# STM32WB55_CM0P register map
File version: 1.7
CPU: CM0 r0p1, little endian, MPU, no FPU, 4 interrupt priority bits
Registers are 32-bit, read-write, reset 0x0 unless marked. A register's access mark holds for its fields unless they carry their own. Offsets are from the block's base; [hi:lo] are bit positions.

## RCC — Reset and clock control
Base 0x58000000
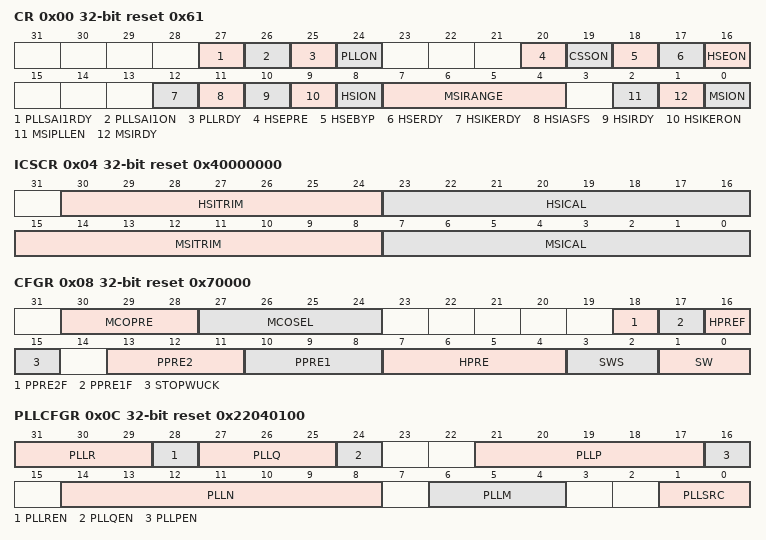
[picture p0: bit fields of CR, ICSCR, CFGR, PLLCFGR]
0x00 CR access per field reset 0x61 — Clock control register
  [27] PLLSAI1RDY ro — SAI1 PLL clock ready flag
  [26] PLLSAI1ON rw — SAI1 PLL enable
  [25] PLLRDY ro — Main PLL clock ready flag
  [24] PLLON rw — Main PLL enable
  [20] HSEPRE rw — HSE sysclk and PLL M divider prescaler
  [19] CSSON wo — HSE Clock security system enable
  [18] HSEBYP rw — HSE crystal oscillator bypass
  [17] HSERDY ro — HSE clock ready flag
  [16] HSEON rw — HSE clock enabled
  [12] HSIKERDY ro — HSI kernel clock ready flag for peripherals requests
  [11] HSIASFS rw — HSI automatic start from Stop
  [10] HSIRDY ro — HSI clock ready flag
  [9] HSIKERON rw — HSI always enable for peripheral kernels
  [8] HSION rw — HSI clock enabled
  [7:4] MSIRANGE rw — MSI clock ranges
  [2] MSIPLLEN rw — MSI clock PLL enable
  [1] MSIRDY ro — MSI clock ready flag
  [0] MSION rw — MSI clock enable
0x04 ICSCR access per field reset 0x40000000 — Internal clock sources calibration register
  [30:24] HSITRIM rw — HSI clock trimming
  [23:16] HSICAL ro — HSI clock calibration
  [15:8] MSITRIM rw — MSI clock trimming
  [7:0] MSICAL ro — MSI clock calibration
0x08 CFGR access per field reset 0x70000 — Clock configuration register
  [30:28] MCOPRE rw — Microcontroller clock output prescaler
  [27:24] MCOSEL rw — Microcontroller clock output
  [18] PPRE2F ro — APB2 prescaler flag
  [17] PPRE1F ro — APB1 prescaler flag
  [16] HPREF ro — AHB prescaler flag
  [15] STOPWUCK rw — Wakeup from Stop and CSS backup clock selection
  [13:11] PPRE2 rw — APB high-speed prescaler (APB2)
  [10:8] PPRE1 rw — PB low-speed prescaler (APB1)
  [7:4] HPRE rw — AHB prescaler
  [3:2] SWS ro — System clock switch status
  [1:0] SW rw — System clock switch
0x0C PLLCFGR reset 0x22040100 — PLLSYS configuration register
  [31:29] PLLR — Main PLLSYS division factor R for SYSCLK (system clock)
  [28] PLLREN — Main PLLSYSR PLLCLK output enable
  [27:25] PLLQ — Main PLLSYS division factor Q for PLLSYSUSBCLK
  [24] PLLQEN — Main PLLSYSQ output enable
  [21:17] PLLP — Main PLL division factor P for PPLSYSSAICLK
  [16] PLLPEN — Main PLLSYSP output enable
  [14:8] PLLN — Main PLLSYS multiplication factor N
  [6:4] PLLM — Division factor M for the main PLL and audio PLL (PLLSAI1 and PLLSAI2) input clock
  [1:0] PLLSRC — Main PLL, PLLSAI1 and PLLSAI2 entry clock source
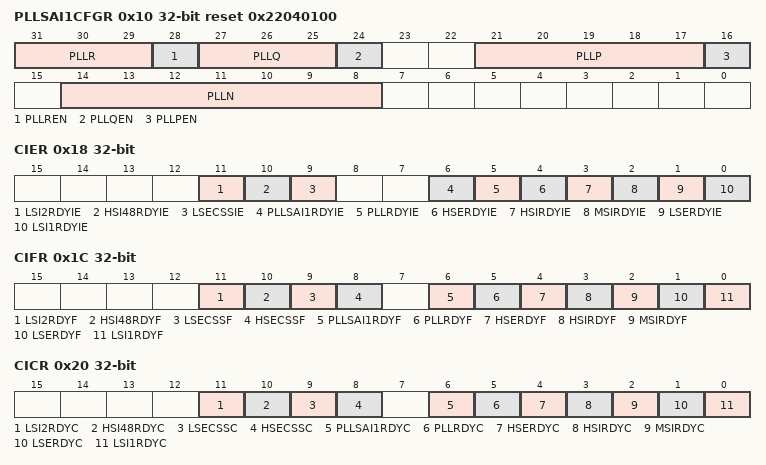
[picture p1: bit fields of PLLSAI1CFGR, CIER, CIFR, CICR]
0x10 PLLSAI1CFGR reset 0x22040100 — PLLSAI1 configuration register
  [31:29] PLLR — PLLSAI division factor R for PLLADC1CLK (ADC clock)
  [28] PLLREN — PLLSAI PLLADC1CLK output enable
  [27:25] PLLQ — SAIPLL division factor Q for PLLSAIUSBCLK (48 MHz clock)
  [24] PLLQEN — SAIPLL PLLSAIUSBCLK output enable
  [21:17] PLLP — SAI1PLL division factor P for PLLSAICLK (SAI1clock)
  [16] PLLPEN — SAIPLL PLLSAI1CLK output enable
  [14:8] PLLN — SAIPLL multiplication factor for VCO
0x18 CIER — Clock interrupt enable register
  [11] LSI2RDYIE — LSI2 ready interrupt enable
  [10] HSI48RDYIE — HSI48 ready interrupt enable
  [9] LSECSSIE — LSE clock security system interrupt enable
  [6] PLLSAI1RDYIE — PLLSAI1 ready interrupt enable
  [5] PLLRDYIE — PLLSYS ready interrupt enable
  [4] HSERDYIE — HSE ready interrupt enable
  [3] HSIRDYIE — HSI ready interrupt enable
  [2] MSIRDYIE — MSI ready interrupt enable
  [1] LSERDYIE — LSE ready interrupt enable
  [0] LSI1RDYIE — LSI1 ready interrupt enable
0x1C CIFR ro — Clock interrupt flag register
  [11] LSI2RDYF — LSI2 ready interrupt flag
  [10] HSI48RDYF — HSI48 ready interrupt flag
  [9] LSECSSF — LSE Clock security system interrupt flag
  [8] HSECSSF — HSE Clock security system interrupt flag
  [6] PLLSAI1RDYF — PLLSAI1 ready interrupt flag
  [5] PLLRDYF — PLL ready interrupt flag
  [4] HSERDYF — HSE ready interrupt flag
  [3] HSIRDYF — HSI ready interrupt flag
  [2] MSIRDYF — MSI ready interrupt flag
  [1] LSERDYF — LSE ready interrupt flag
  [0] LSI1RDYF — LSI1 ready interrupt flag
0x20 CICR wo — Clock interrupt clear register
  [11] LSI2RDYC — LSI2 ready interrupt clear
  [10] HSI48RDYC — HSI48 ready interrupt clear
  [9] LSECSSC — LSE Clock security system interrupt clear
  [8] HSECSSC — HSE Clock security system interrupt clear
  [6] PLLSAI1RDYC — PLLSAI1 ready interrupt clear
  [5] PLLRDYC — PLL ready interrupt clear
  [4] HSERDYC — HSE ready interrupt clear
  [3] HSIRDYC — HSI ready interrupt clear
  [2] MSIRDYC — MSI ready interrupt clear
  [1] LSERDYC — LSE ready interrupt clear
  [0] LSI1RDYC — LSI1 ready interrupt clear
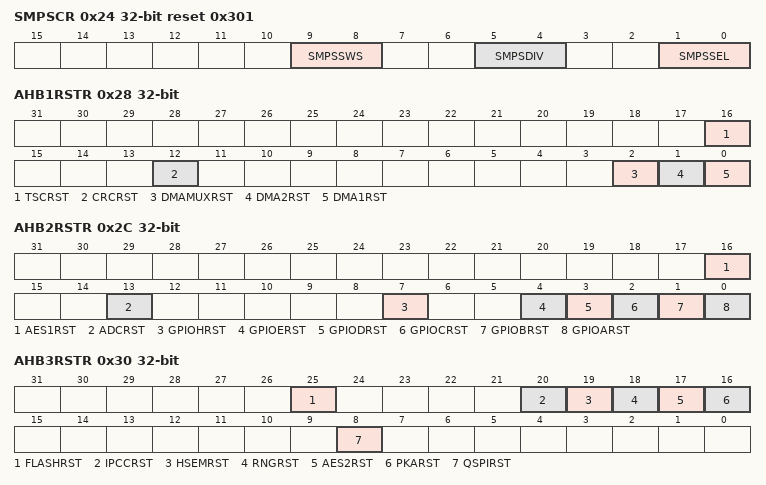
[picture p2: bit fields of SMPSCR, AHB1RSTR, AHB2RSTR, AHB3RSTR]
0x24 SMPSCR access per field reset 0x301 — Step Down converter control register
  [9:8] SMPSSWS ro — Step Down converter clock switch status
  [5:4] SMPSDIV rw — Step Down converter clock prescaler
  [1:0] SMPSSEL rw — Step Down converter clock selection
0x28 AHB1RSTR — AHB1 peripheral reset register
  [16] TSCRST — Touch Sensing Controller reset
  [12] CRCRST — CRC reset
  [2] DMAMUXRST — DMAMUX reset
  [1] DMA2RST — DMA2 reset
  [0] DMA1RST — DMA1 reset
0x2C AHB2RSTR — AHB2 peripheral reset register
  [16] AES1RST — AES1 hardware accelerator reset
  [13] ADCRST — ADC reset
  [7] GPIOHRST — IO port H reset
  [4] GPIOERST — IO port E reset
  [3] GPIODRST — IO port D reset
  [2] GPIOCRST — IO port C reset
  [1] GPIOBRST — IO port B reset
  [0] GPIOARST — IO port A reset
0x30 AHB3RSTR — AHB3 peripheral reset register
  [25] FLASHRST — Flash interface reset
  [20] IPCCRST — IPCC interface reset
  [19] HSEMRST — HSEM interface reset
  [18] RNGRST — RNG interface reset
  [17] AES2RST — AES2 interface reset
  [16] PKARST — PKA interface reset
  [8] QSPIRST — Quad SPI memory interface reset
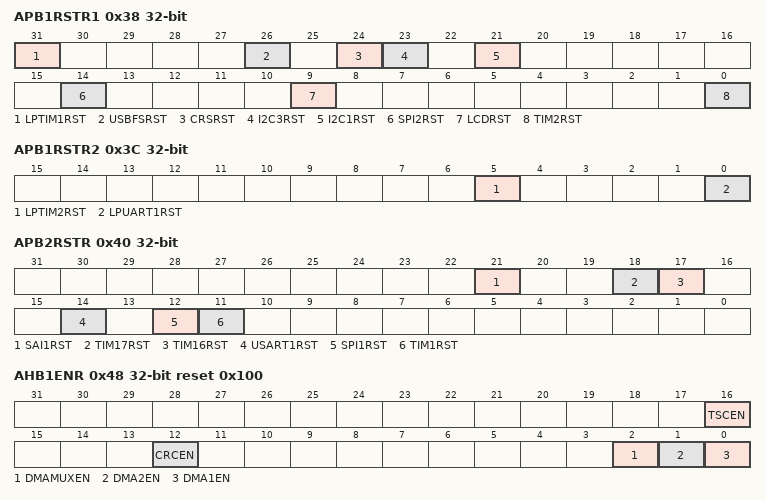
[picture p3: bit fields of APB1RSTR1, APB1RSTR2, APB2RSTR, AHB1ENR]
0x38 APB1RSTR1 — APB1 peripheral reset register 1
  [31] LPTIM1RST — Low Power Timer 1 reset
  [26] USBFSRST — USB FS reset
  [24] CRSRST — CRS reset
  [23] I2C3RST — I2C3 reset
  [21] I2C1RST — I2C1 reset
  [14] SPI2RST — SPI2 reset
  [9] LCDRST — LCD interface reset
  [0] TIM2RST — TIM2 timer reset
0x3C APB1RSTR2 — APB1 peripheral reset register 2
  [5] LPTIM2RST — Low-power timer 2 reset
  [0] LPUART1RST — Low-power UART 1 reset
0x40 APB2RSTR — APB2 peripheral reset register
  [21] SAI1RST — Serial audio interface 1 (SAI1) reset
  [18] TIM17RST — TIM17 timer reset
  [17] TIM16RST — TIM16 timer reset
  [14] USART1RST — USART1 reset
  [12] SPI1RST — SPI1 reset
  [11] TIM1RST — TIM1 timer reset
0x44 APB3RSTR — APB3 peripheral reset register
  [0] RFRST — Radio system BLE reset
0x48 AHB1ENR reset 0x100 — AHB1 peripheral clock enable register
  [16] TSCEN — Touch Sensing Controller clock enable
  [12] CRCEN — CPU1 CRC clock enable
  [2] DMAMUXEN — DMAMUX clock enable
  [1] DMA2EN — DMA2 clock enable
  [0] DMA1EN — DMA1 clock enable
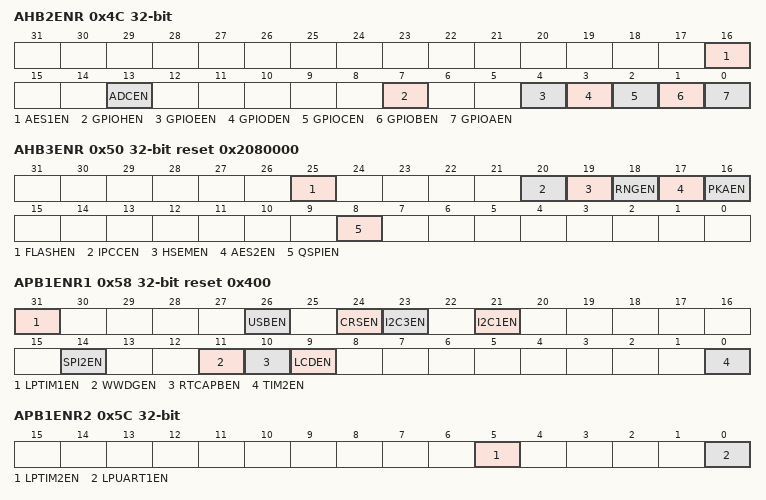
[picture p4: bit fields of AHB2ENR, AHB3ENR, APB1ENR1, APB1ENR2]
0x4C AHB2ENR — AHB2 peripheral clock enable register
  [16] AES1EN — AES1 accelerator clock enable
  [13] ADCEN — ADC clock enable
  [7] GPIOHEN — IO port H clock enable
  [4] GPIOEEN — IO port E clock enable
  [3] GPIODEN — IO port D clock enable
  [2] GPIOCEN — IO port C clock enable
  [1] GPIOBEN — IO port B clock enable
  [0] GPIOAEN — IO port A clock enable
0x50 AHB3ENR reset 0x2080000 — AHB3 peripheral clock enable register
  [25] FLASHEN, [20] IPCCEN, [19] HSEMEN, [18] RNGEN, [17] AES2EN, [16] PKAEN, [8] QSPIEN
0x58 APB1ENR1 reset 0x400
  [31] LPTIM1EN — CPU1 Low power timer 1 clock enable
  [26] USBEN — CPU1 USB clock enable
  [24] CRSEN — CPU1 CRS clock enable
  [23] I2C3EN — CPU1 I2C3 clock enable
  [21] I2C1EN — CPU1 I2C1 clock enable
  [14] SPI2EN — CPU1 SPI2 clock enable
  [11] WWDGEN — CPU1 Window watchdog clock enable
  [10] RTCAPBEN — CPU1 RTC APB clock enable
  [9] LCDEN — CPU1 LCD clock enable
  [0] TIM2EN — CPU1 TIM2 timer clock enable
0x5C APB1ENR2 — APB1 peripheral clock enable register 2
  [5] LPTIM2EN — CPU1 LPTIM2EN
  [0] LPUART1EN — CPU1 Low power UART 1 clock enable
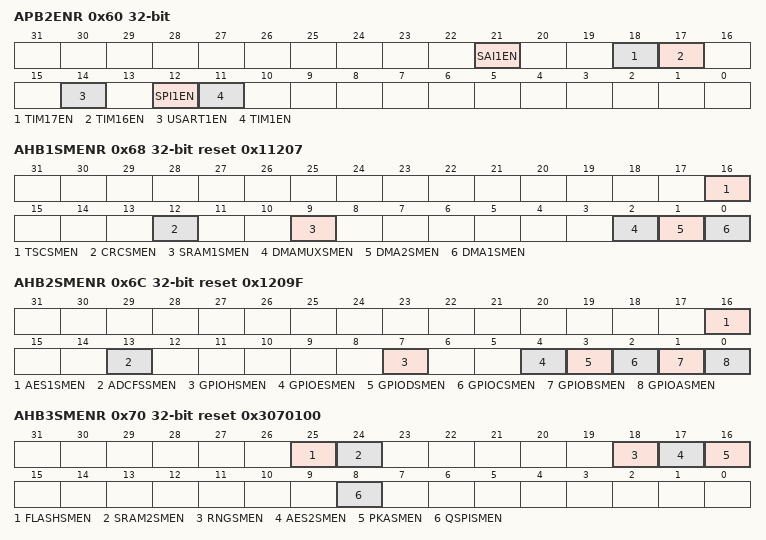
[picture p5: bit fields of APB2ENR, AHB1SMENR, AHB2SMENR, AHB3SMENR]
0x60 APB2ENR
  [21] SAI1EN — CPU1 SAI1 clock enable
  [18] TIM17EN — CPU1 TIM17 timer clock enable
  [17] TIM16EN — CPU1 TIM16 timer clock enable
  [14] USART1EN — CPU1 USART1clock enable
  [12] SPI1EN — CPU1 SPI1 clock enable
  [11] TIM1EN — CPU1 TIM1 timer clock enable
0x68 AHB1SMENR reset 0x11207 — AHB1 peripheral clocks enable in Sleep and Stop modes register
  [16] TSCSMEN — CPU1 Touch Sensing Controller clocks enable during Sleep and Stop modes
  [12] CRCSMEN — CPU1 CRCSMEN
  [9] SRAM1SMEN — CPU1 SRAM1 interface clocks enable during Sleep and Stop modes
  [2] DMAMUXSMEN — CPU1 DMAMUX clocks enable during Sleep and Stop modes
  [1] DMA2SMEN — CPU1 DMA2 clocks enable during Sleep and Stop modes
  [0] DMA1SMEN — CPU1 DMA1 clocks enable during Sleep and Stop modes
0x6C AHB2SMENR reset 0x1209F — AHB2 peripheral clocks enable in Sleep and Stop modes register
  [16] AES1SMEN — CPU1 AES1 accelerator clocks enable during Sleep and Stop modes
  [13] ADCFSSMEN — CPU1 ADC clocks enable during Sleep and Stop modes
  [7] GPIOHSMEN — CPU1 IO port H clocks enable during Sleep and Stop modes
  [4] GPIOESMEN — CPU1 IO port E clocks enable during Sleep and Stop modes
  [3] GPIODSMEN — CPU1 IO port D clocks enable during Sleep and Stop modes
  [2] GPIOCSMEN — CPU1 IO port C clocks enable during Sleep and Stop modes
  [1] GPIOBSMEN — CPU1 IO port B clocks enable during Sleep and Stop modes
  [0] GPIOASMEN — CPU1 IO port A clocks enable during Sleep and Stop modes
0x70 AHB3SMENR reset 0x3070100 — AHB3 peripheral clocks enable in Sleep and Stop modes register
  [25] FLASHSMEN — Flash interface clocks enable during CPU1 sleep mode
  [24] SRAM2SMEN — SRAM2a and SRAM2b memory interface clocks enable during CPU1 sleep mode
  [18] RNGSMEN — True RNG clocks enable during CPU1 sleep mode
  [17] AES2SMEN — AES2 accelerator clocks enable during CPU1 sleep mode
  [16] PKASMEN — PKA accelerator clocks enable during CPU1 sleep mode
  [8] QSPISMEN
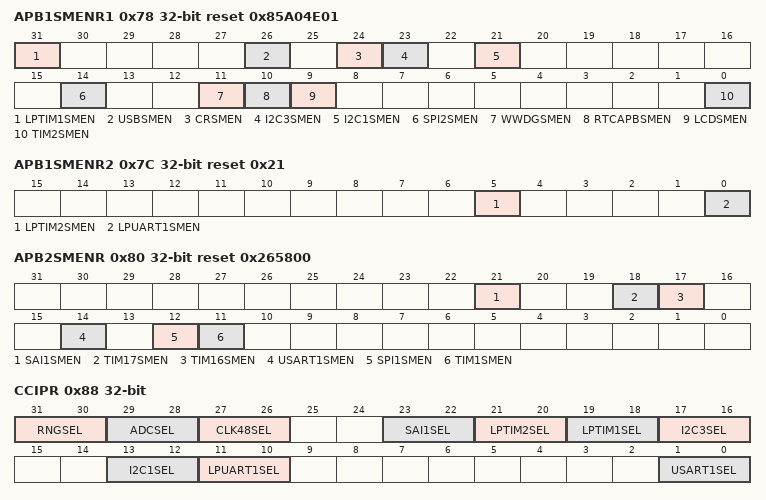
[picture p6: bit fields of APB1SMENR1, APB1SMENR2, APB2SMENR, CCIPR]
0x78 APB1SMENR1 reset 0x85A04E01
  [31] LPTIM1SMEN — Low power timer 1 clocks enable during CPU1 Sleep mode
  [26] USBSMEN — USB FS clocks enable during CPU1 Sleep mode
  [24] CRSMEN — CRS clocks enable during CPU1 Sleep mode
  [23] I2C3SMEN — I2C3 clocks enable during CPU1 Sleep mode
  [21] I2C1SMEN — I2C1 clocks enable during CPU1 Sleep mode
  [14] SPI2SMEN — SPI2 clocks enable during CPU1 Sleep mode
  [11] WWDGSMEN — Window watchdog clocks enable during CPU1 Sleep mode
  [10] RTCAPBSMEN — RTC APB clocks enable during CPU1 Sleep mode
  [9] LCDSMEN — LCD clocks enable during CPU1 Sleep mode
  [0] TIM2SMEN — TIM2 timer clocks enable during CPU1 Sleep mode
0x7C APB1SMENR2 reset 0x21 — APB1 peripheral clocks enable in Sleep and Stop modes register 2
  [5] LPTIM2SMEN — Low power timer 2 clocks enable during CPU1 Sleep mode
  [0] LPUART1SMEN — Low power UART 1 clocks enable during CPU1 Sleep mode
0x80 APB2SMENR reset 0x265800
  [21] SAI1SMEN — SAI1 clocks enable during CPU1 Sleep mode
  [18] TIM17SMEN — TIM17 timer clocks enable during CPU1 Sleep mode
  [17] TIM16SMEN — TIM16 timer clocks enable during CPU1 Sleep mode
  [14] USART1SMEN — USART1clocks enable during CPU1 Sleep mode
  [12] SPI1SMEN — SPI1 clocks enable during CPU1 Sleep mode
  [11] TIM1SMEN — TIM1 timer clocks enable during CPU1 Sleep mode
0x88 CCIPR
  [31:30] RNGSEL — RNG clock source selection
  [29:28] ADCSEL — ADCs clock source selection
  [27:26] CLK48SEL — 48 MHz clock source selection
  [23:22] SAI1SEL — SAI1 clock source selection
  [21:20] LPTIM2SEL — Low power timer 2 clock source selection
  [19:18] LPTIM1SEL — Low power timer 1 clock source selection
  [17:16] I2C3SEL — I2C3 clock source selection
  [13:12] I2C1SEL — I2C1 clock source selection
  [11:10] LPUART1SEL — LPUART1 clock source selection
  [1:0] USART1SEL — USART1 clock source selection
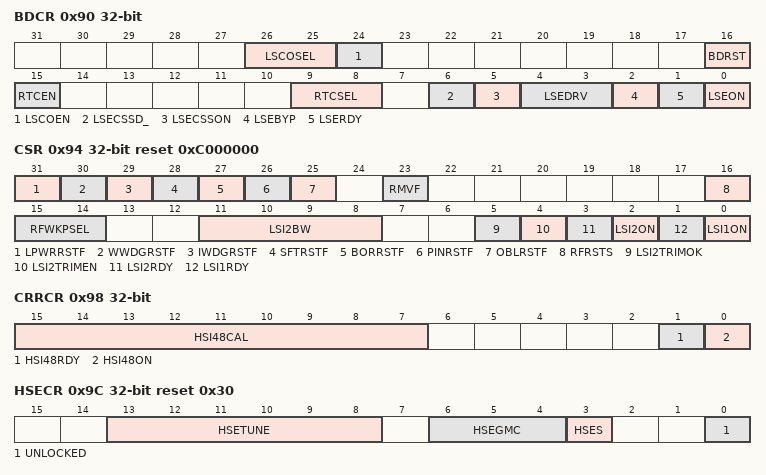
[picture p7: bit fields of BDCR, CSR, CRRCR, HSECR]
0x90 BDCR access per field
  [26:25] LSCOSEL rw — Low speed clock output selection
  [24] LSCOEN rw — Low speed clock output enable
  [16] BDRST rw — Backup domain software reset
  [15] RTCEN rw — RTC clock enable
  [9:8] RTCSEL rw — RTC clock source selection
  [6] LSECSSD_ ro — CSS on LSE failure detection
  [5] LSECSSON rw
  [4:3] LSEDRV rw — SE oscillator drive capability
  [2] LSEBYP rw — LSE oscillator bypass
  [1] LSERDY ro — LSE oscillator ready
  [0] LSEON rw — LSE oscillator enable
0x94 CSR access per field reset 0xC000000
  [31] LPWRRSTF ro — Low-power reset flag
  [30] WWDGRSTF ro — Window watchdog reset flag
  [29] IWDGRSTF ro — Independent window watchdog reset flag
  [28] SFTRSTF ro — Software reset flag
  [27] BORRSTF ro — BOR flag
  [26] PINRSTF ro — Pin reset flag
  [25] OBLRSTF ro — Option byte loader reset flag
  [23] RMVF rw — Remove reset flag
  [16] RFRSTS ro — Radio system BLE and 802.15.4 reset status
  [15:14] RFWKPSEL rw — RF system wakeup clock source selection
  [11:8] LSI2BW rw — LSI2 oscillator bias configuration
  [5] LSI2TRIMOK ro — LSI2 oscillator trim OK
  [4] LSI2TRIMEN rw — LSI2 oscillator trimming enable
  [3] LSI2RDY ro — LSI2 oscillator ready
  [2] LSI2ON rw — LSI2 oscillator enabled
  [1] LSI1RDY ro — LSI1 oscillator ready
  [0] LSI1ON rw — LSI1 oscillator enabled
0x98 CRRCR access per field — Clock recovery RC register
  [15:7] HSI48CAL ro — HSI48 clock calibration
  [1] HSI48RDY ro — HSI48 clock ready
  [0] HSI48ON rw — HSI48 oscillator enabled
0x9C HSECR access per field reset 0x30 — Clock HSE register
  [13:8] HSETUNE ro — HSE capacitor tuning
  [6:4] HSEGMC rw — HSE current control
  [3] HSES rw — HSE Sense amplifier threshold
  [0] UNLOCKED rw — Register lock system
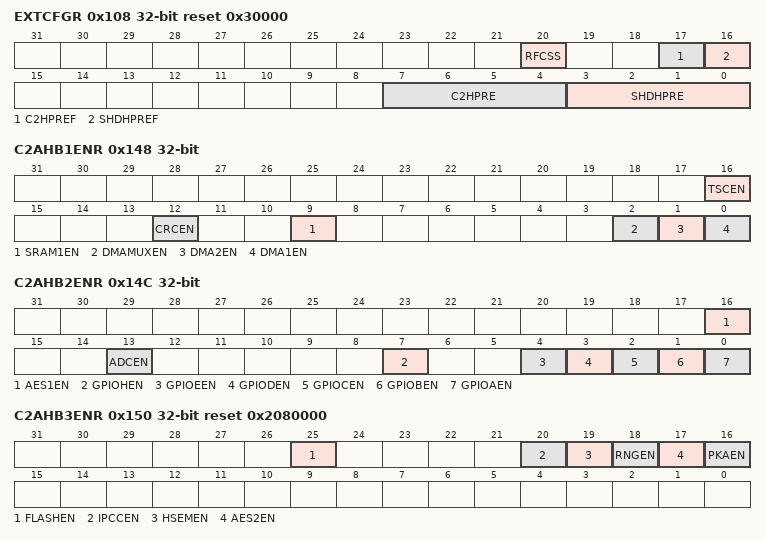
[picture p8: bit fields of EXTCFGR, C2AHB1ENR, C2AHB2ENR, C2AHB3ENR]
0x108 EXTCFGR access per field reset 0x30000 — Extended clock recovery register
  [20] RFCSS ro — RF clock source selected
  [17] C2HPREF ro — CPU2 AHB prescaler flag
  [16] SHDHPREF ro — Shared AHB prescaler flag
  [7:4] C2HPRE rw — CPU2 AHB prescaler
  [3:0] SHDHPRE rw — Shared AHB prescaler
0x148 C2AHB1ENR — CPU2 AHB1 peripheral clock enable register
  [16] TSCEN — CPU2 Touch Sensing Controller clock enable
  [12] CRCEN — CPU2 CRC clock enable
  [9] SRAM1EN — CPU2 SRAM1 clock enable
  [2] DMAMUXEN — CPU2 DMAMUX clock enable
  [1] DMA2EN — CPU2 DMA2 clock enable
  [0] DMA1EN — CPU2 DMA1 clock enable
0x14C C2AHB2ENR — CPU2 AHB2 peripheral clock enable register
  [16] AES1EN — CPU2 AES1 accelerator clock enable
  [13] ADCEN — CPU2 ADC clock enable
  [7] GPIOHEN — CPU2 IO port H clock enable
  [4] GPIOEEN — CPU2 IO port E clock enable
  [3] GPIODEN — CPU2 IO port D clock enable
  [2] GPIOCEN — CPU2 IO port C clock enable
  [1] GPIOBEN — CPU2 IO port B clock enable
  [0] GPIOAEN — CPU2 IO port A clock enable
0x150 C2AHB3ENR reset 0x2080000 — CPU2 AHB3 peripheral clock enable register
  [25] FLASHEN — CPU2 FLASHEN
  [20] IPCCEN — CPU2 IPCCEN
  [19] HSEMEN — CPU2 HSEMEN
  [18] RNGEN — CPU2 RNGEN
  [17] AES2EN — CPU2 AES2EN
  [16] PKAEN — CPU2 PKAEN
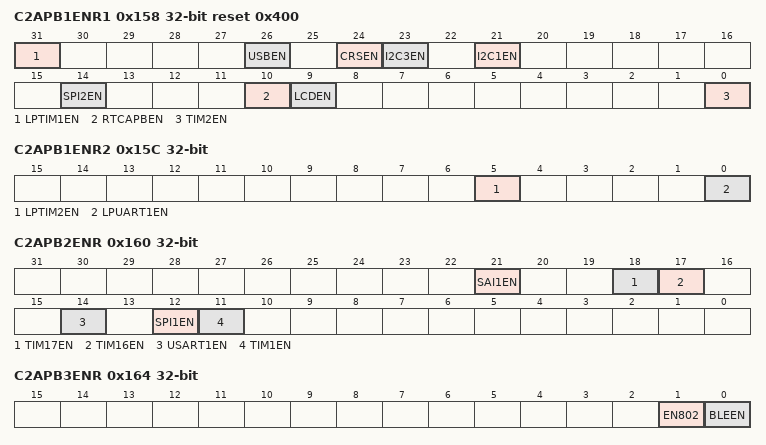
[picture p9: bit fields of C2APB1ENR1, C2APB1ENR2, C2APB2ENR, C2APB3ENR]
0x158 C2APB1ENR1 reset 0x400 — CPU2 APB1ENR1
  [31] LPTIM1EN — CPU2 Low power timer 1 clock enable
  [26] USBEN — CPU2 USB clock enable
  [24] CRSEN — CPU2 CRS clock enable
  [23] I2C3EN — CPU2 I2C3 clock enable
  [21] I2C1EN — CPU2 I2C1 clock enable
  [14] SPI2EN — CPU2 SPI2 clock enable
  [10] RTCAPBEN — CPU2 RTC APB clock enable
  [9] LCDEN — CPU2 LCD clock enable
  [0] TIM2EN — CPU2 TIM2 timer clock enable
0x15C C2APB1ENR2 — CPU2 APB1 peripheral clock enable register 2
  [5] LPTIM2EN — CPU2 LPTIM2EN
  [0] LPUART1EN — CPU2 Low power UART 1 clock enable
0x160 C2APB2ENR — CPU2 APB2ENR
  [21] SAI1EN — CPU2 SAI1 clock enable
  [18] TIM17EN — CPU2 TIM17 timer clock enable
  [17] TIM16EN — CPU2 TIM16 timer clock enable
  [14] USART1EN — CPU2 USART1clock enable
  [12] SPI1EN — CPU2 SPI1 clock enable
  [11] TIM1EN — CPU2 TIM1 timer clock enable
0x164 C2APB3ENR — CPU2 APB3ENR
  [1] EN802 — CPU2 802.15.4 interface clock enable
  [0] BLEEN — CPU2 BLE interface clock enable
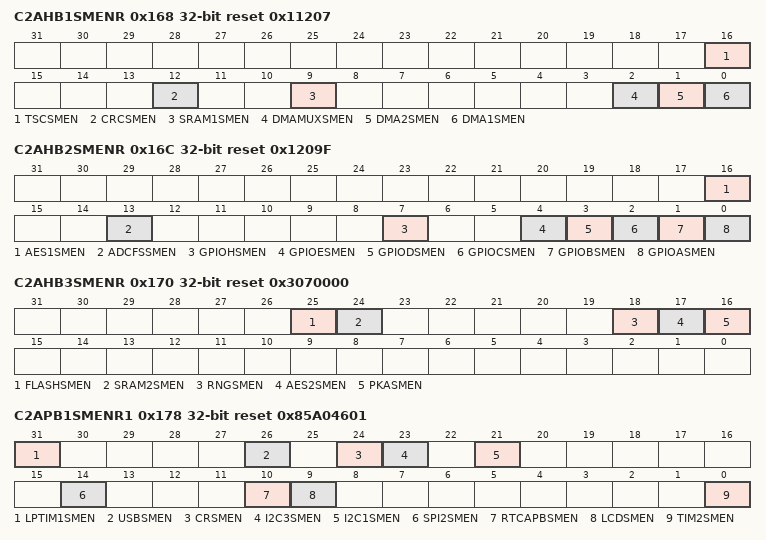
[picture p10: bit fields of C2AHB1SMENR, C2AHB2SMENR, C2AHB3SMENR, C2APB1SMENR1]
0x168 C2AHB1SMENR reset 0x11207 — CPU2 AHB1 peripheral clocks enable in Sleep and Stop modes register
  [16] TSCSMEN — CPU2 Touch Sensing Controller clocks enable during Sleep and Stop modes
  [12] CRCSMEN — CPU2 CRCSMEN
  [9] SRAM1SMEN — SRAM1 interface clock enable during CPU1 CSleep mode
  [2] DMAMUXSMEN — CPU2 DMAMUX clocks enable during Sleep and Stop modes
  [1] DMA2SMEN — CPU2 DMA2 clocks enable during Sleep and Stop modes
  [0] DMA1SMEN — CPU2 DMA1 clocks enable during Sleep and Stop modes
0x16C C2AHB2SMENR reset 0x1209F — CPU2 AHB2 peripheral clocks enable in Sleep and Stop modes register
  [16] AES1SMEN — CPU2 AES1 accelerator clocks enable during Sleep and Stop modes
  [13] ADCFSSMEN — CPU2 ADC clocks enable during Sleep and Stop modes
  [7] GPIOHSMEN — CPU2 IO port H clocks enable during Sleep and Stop modes
  [4] GPIOESMEN — CPU2 IO port E clocks enable during Sleep and Stop modes
  [3] GPIODSMEN — CPU2 IO port D clocks enable during Sleep and Stop modes
  [2] GPIOCSMEN — CPU2 IO port C clocks enable during Sleep and Stop modes
  [1] GPIOBSMEN — CPU2 IO port B clocks enable during Sleep and Stop modes
  [0] GPIOASMEN — CPU2 IO port A clocks enable during Sleep and Stop modes
0x170 C2AHB3SMENR reset 0x3070000 — CPU2 AHB3 peripheral clocks enable in Sleep and Stop modes register
  [25] FLASHSMEN — Flash interface clocks enable during CPU2 sleep modes
  [24] SRAM2SMEN — SRAM2a and SRAM2b memory interface clocks enable during CPU2 sleep modes
  [18] RNGSMEN — True RNG clocks enable during CPU2 sleep modes
  [17] AES2SMEN — AES2 accelerator clocks enable during CPU2 sleep modes
  [16] PKASMEN — PKA accelerator clocks enable during CPU2 sleep modes
0x178 C2APB1SMENR1 reset 0x85A04601 — CPU2 APB1SMENR1
  [31] LPTIM1SMEN — Low power timer 1 clocks enable during CPU2 Sleep mode
  [26] USBSMEN — USB FS clocks enable during CPU2 Sleep mode
  [24] CRSMEN — CRS clocks enable during CPU2 Sleep mode
  [23] I2C3SMEN — I2C3 clocks enable during CPU2 Sleep mode
  [21] I2C1SMEN — I2C1 clocks enable during CPU2 Sleep mode
  [14] SPI2SMEN — SPI2 clocks enable during CPU2 Sleep mode
  [10] RTCAPBSMEN — RTC APB clocks enable during CPU2 Sleep mode
  [9] LCDSMEN — LCD clocks enable during CPU2 Sleep mode
  [0] TIM2SMEN — TIM2 timer clocks enable during CPU2 Sleep mode
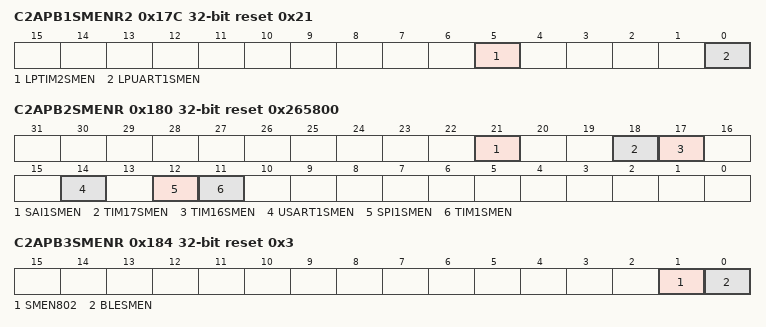
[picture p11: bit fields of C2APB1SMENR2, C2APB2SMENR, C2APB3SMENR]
0x17C C2APB1SMENR2 reset 0x21 — CPU2 APB1 peripheral clocks enable in Sleep and Stop modes register 2
  [5] LPTIM2SMEN — Low power timer 2 clocks enable during CPU2 Sleep mode
  [0] LPUART1SMEN — Low power UART 1 clocks enable during CPU2 Sleep mode
0x180 C2APB2SMENR reset 0x265800 — CPU2 APB2SMENR
  [21] SAI1SMEN — SAI1 clocks enable during CPU2 Sleep mode
  [18] TIM17SMEN — TIM17 timer clocks enable during CPU2 Sleep mode
  [17] TIM16SMEN — TIM16 timer clocks enable during CPU2 Sleep mode
  [14] USART1SMEN — USART1clocks enable during CPU2 Sleep mode
  [12] SPI1SMEN — SPI1 clocks enable during CPU2 Sleep mode
  [11] TIM1SMEN — TIM1 timer clocks enable during CPU2 Sleep mode
0x184 C2APB3SMENR reset 0x3 — CPU2 APB3SMENR
  [1] SMEN802 — 802.15.4 interface clocks enable during CPU2 Sleep modes
  [0] BLESMEN — BLE interface clocks enable during CPU2 Sleep mode
